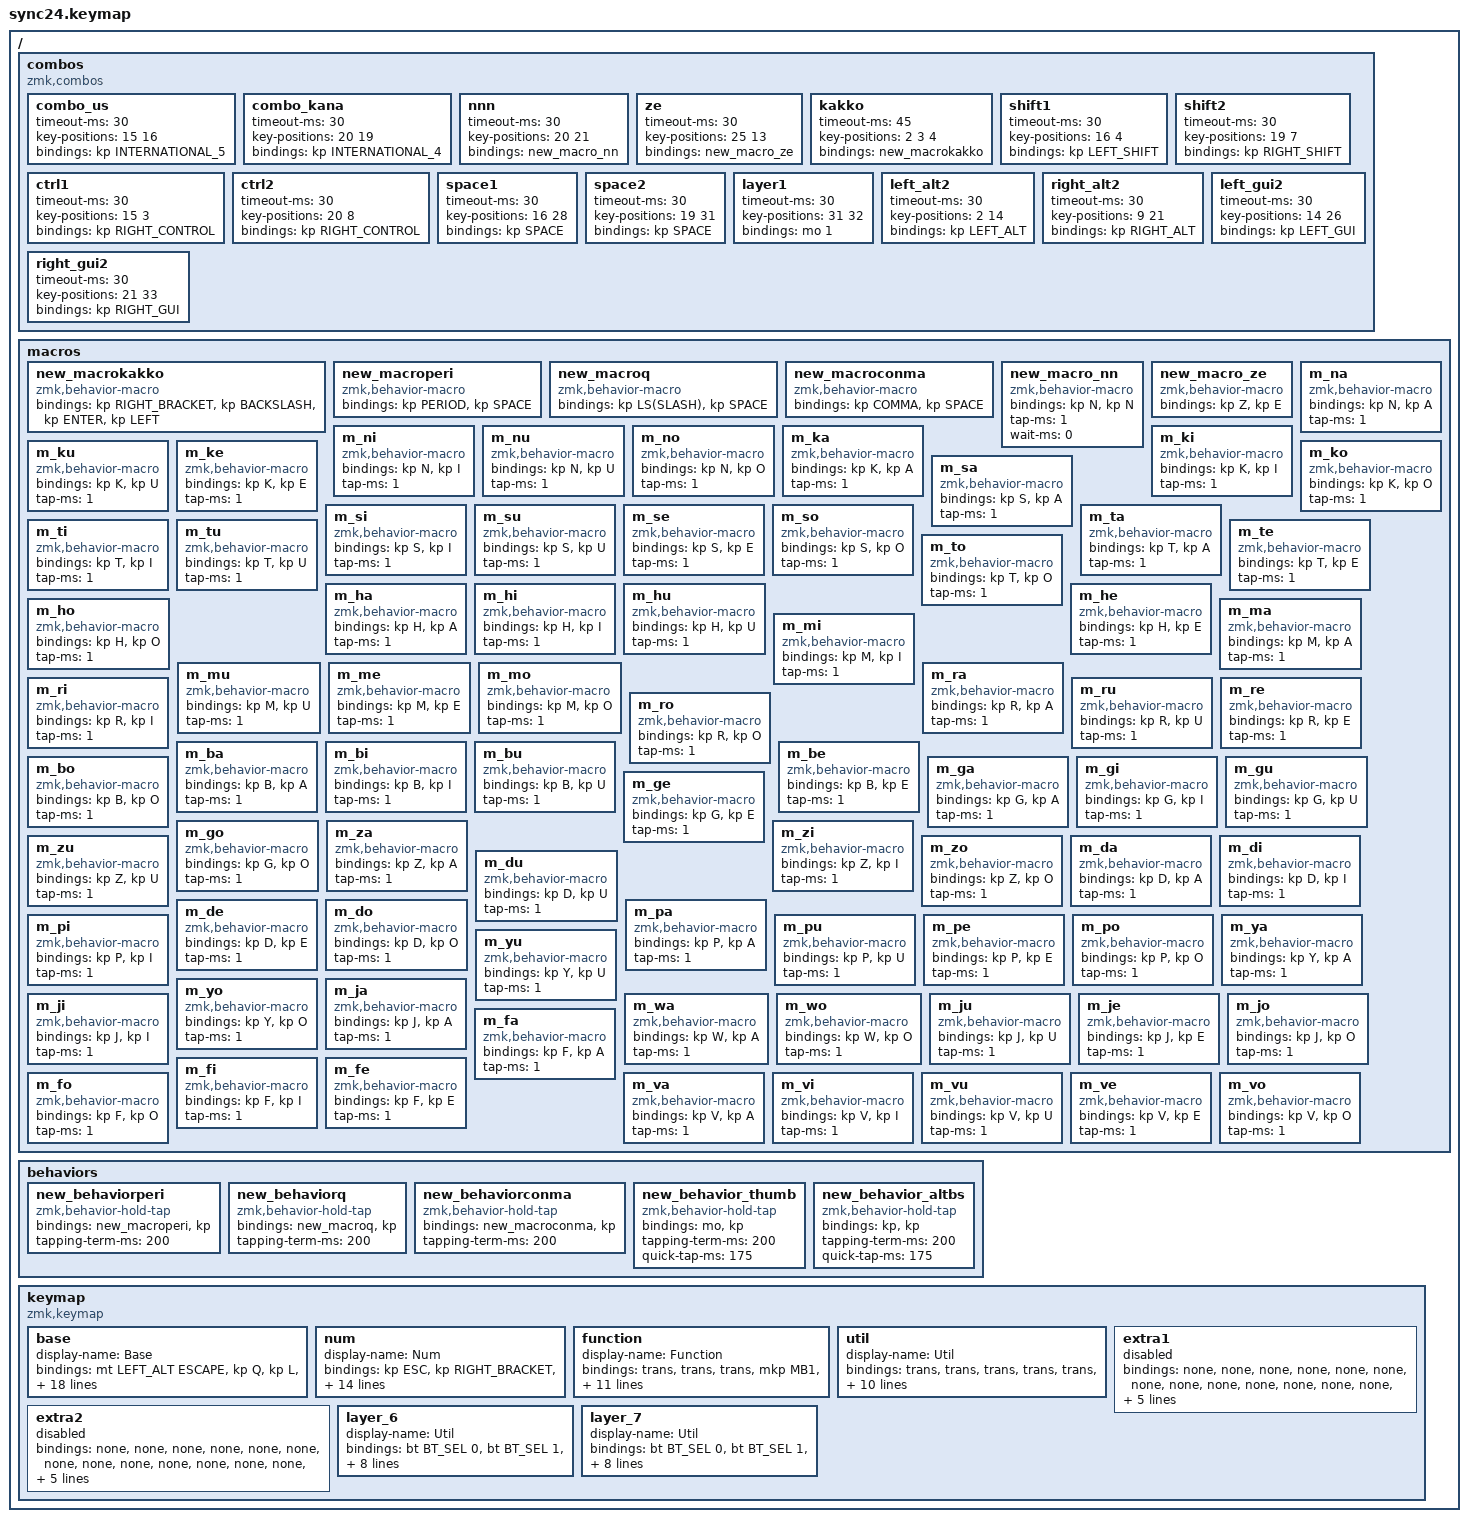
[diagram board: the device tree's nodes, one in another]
#define ZMK_BEHAVIORS_OMIT_KT

#undef ZMK_BEHAVIORS_KEEP_ALL

#define ZMK_BEHAVIORS_KEEP_SK
#define ZMK_BEHAVIORS_KEEP_MT
#define ZMK_BEHAVIORS_KEEP_KT

#include <behaviors.dtsi>
#include <dt-bindings/zmk/bt.h>
#include <dt-bindings/zmk/keys.h>
#include <dt-bindings/zmk/outputs.h>
#include <dt-bindings/zmk/pointing.h>

/ {
    /* ==========================================================================
       Combos
       ========================================================================== */

    combos {
        compatible = "zmk,combos";

        // 1. 特殊・ユーティリティ (最速判定)

        combo_us {
            timeout-ms = <30>;
            key-positions = <15 16>;
            bindings = <&kp INTERNATIONAL_5>;
        };

        combo_kana {
            timeout-ms = <30>;
            key-positions = <20 19>;
            bindings = <&kp INTERNATIONAL_4>;
        };

        nnn {
            timeout-ms = <30>;
            key-positions = <20 21>;
            bindings = <&new_macro_nn>;
        };

        ze {
            timeout-ms = <30>;
            key-positions = <25 13>;
            bindings = <&new_macro_ze>;
        };

        // 2. ★ 4文字・頻出語句コンボ (Timeout: 45ms)
        // んな // んに // んぬ // んね // んの // S+H+O+U // K+Y+O+U // T+Y+O+U // R+Y+O+U
        // ★ここを差し替え（です/ます等を A+O 系に変更し、末尾に . + Space）
        // A+O+T -> desu.(space) // A+O+S -> ました.(space) // A+O+D -> desita.(space) // A+O+N -> ます.(space) // A+O+N+S -> masenn.(space) // A+O+Y -> deshou.(space) // K+A+O // M+A+O // G+O+A // S+I+T+A
        // 3. 3文字コンボ (Timeout: 45ms)
        // 4. 2文字コンボ (Timeout: 30ms)
        // I+U どちらが先でもOK
        // 5. モディファイア・その他

        kakko {
            timeout-ms = <45>;
            key-positions = <2 3 4>;
            bindings = <&new_macrokakko>;
        };

        shift1 {
            timeout-ms = <30>;
            key-positions = <16 4>;
            bindings = <&kp LEFT_SHIFT>;
        };

        shift2 {
            timeout-ms = <30>;
            key-positions = <19 7>;
            bindings = <&kp RIGHT_SHIFT>;
        };

        ctrl1 {
            timeout-ms = <30>;
            key-positions = <15 3>;
            bindings = <&kp RIGHT_CONTROL>;
        };

        ctrl2 {
            timeout-ms = <30>;
            key-positions = <20 8>;
            bindings = <&kp RIGHT_CONTROL>;
        };

        space1 {
            timeout-ms = <30>;
            key-positions = <16 28>;
            bindings = <&kp SPACE>;
        };

        space2 {
            timeout-ms = <30>;
            key-positions = <19 31>;
            bindings = <&kp SPACE>;
        };

        layer1 {
            timeout-ms = <30>;
            key-positions = <31 32>;
            bindings = <&mo 1>;
        };

        left_alt2 {
            timeout-ms = <30>;
            key-positions = <2 14>;
            bindings = <&kp LEFT_ALT>;
        };

        right_alt2 {
            timeout-ms = <30>;
            key-positions = <9 21>;
            bindings = <&kp RIGHT_ALT>;
        };

        left_gui2 {
            timeout-ms = <30>;
            key-positions = <14 26>;
            bindings = <&kp LEFT_GUI>;
        };

        right_gui2 {
            timeout-ms = <30>;
            key-positions = <21 33>;
            bindings = <&kp RIGHT_GUI>;
        };
    };

    /* ==========================================================================
       Macros
       ========================================================================== */

    macros {
        new_macrokakko: new_macrokakko {
            compatible = "zmk,behavior-macro";
            #binding-cells = <0>;
            bindings = <&kp RIGHT_BRACKET &kp BACKSLASH &kp ENTER &kp LEFT>;
        };

        new_macroperi: new_macroperi {
            compatible = "zmk,behavior-macro";
            #binding-cells = <0>;
            bindings = <&kp PERIOD &kp SPACE>;
        };

        new_macroq: new_macroq {
            compatible = "zmk,behavior-macro";
            #binding-cells = <0>;
            bindings = <&kp LS(SLASH) &kp SPACE>;
        };

        new_macroconma: new_macroconma {
            compatible = "zmk,behavior-macro";
            #binding-cells = <0>;
            bindings = <&kp COMMA &kp SPACE>;
        };

        new_macro_nn: new_macro_nn {
            compatible = "zmk,behavior-macro";
            #binding-cells = <0>;
            bindings = <&kp N &kp N>;
            tap-ms = <1>;
            wait-ms = <0>;
        };

        new_macro_ze: new_macro_ze {
            compatible = "zmk,behavior-macro";
            #binding-cells = <0>;
            bindings = <&kp Z &kp E>;
        };

        // ★追加：末尾に「. + Space」を付ける版

        m_na: m_na {
            compatible = "zmk,behavior-macro";
            #binding-cells = <0>;
            bindings = <&kp N &kp A>;
            tap-ms = <1>;
        };

        m_ni: m_ni {
            compatible = "zmk,behavior-macro";
            #binding-cells = <0>;
            bindings = <&kp N &kp I>;
            tap-ms = <1>;
        };

        m_nu: m_nu {
            compatible = "zmk,behavior-macro";
            #binding-cells = <0>;
            bindings = <&kp N &kp U>;
            tap-ms = <1>;
        };

        m_no: m_no {
            compatible = "zmk,behavior-macro";
            #binding-cells = <0>;
            bindings = <&kp N &kp O>;
            tap-ms = <1>;
        };

        m_ka: m_ka {
            compatible = "zmk,behavior-macro";
            #binding-cells = <0>;
            bindings = <&kp K &kp A>;
            tap-ms = <1>;
        };

        m_ki: m_ki {
            compatible = "zmk,behavior-macro";
            #binding-cells = <0>;
            bindings = <&kp K &kp I>;
            tap-ms = <1>;
        };

        m_ku: m_ku {
            compatible = "zmk,behavior-macro";
            #binding-cells = <0>;
            bindings = <&kp K &kp U>;
            tap-ms = <1>;
        };

        m_ke: m_ke {
            compatible = "zmk,behavior-macro";
            #binding-cells = <0>;
            bindings = <&kp K &kp E>;
            tap-ms = <1>;
        };

        m_ko: m_ko {
            compatible = "zmk,behavior-macro";
            #binding-cells = <0>;
            bindings = <&kp K &kp O>;
            tap-ms = <1>;
        };

        m_sa: m_sa {
            compatible = "zmk,behavior-macro";
            #binding-cells = <0>;
            bindings = <&kp S &kp A>;
            tap-ms = <1>;
        };

        m_si: m_si {
            compatible = "zmk,behavior-macro";
            #binding-cells = <0>;
            bindings = <&kp S &kp I>;
            tap-ms = <1>;
        };

        m_su: m_su {
            compatible = "zmk,behavior-macro";
            #binding-cells = <0>;
            bindings = <&kp S &kp U>;
            tap-ms = <1>;
        };

        m_se: m_se {
            compatible = "zmk,behavior-macro";
            #binding-cells = <0>;
            bindings = <&kp S &kp E>;
            tap-ms = <1>;
        };

        m_so: m_so {
            compatible = "zmk,behavior-macro";
            #binding-cells = <0>;
            bindings = <&kp S &kp O>;
            tap-ms = <1>;
        };

        m_ta: m_ta {
            compatible = "zmk,behavior-macro";
            #binding-cells = <0>;
            bindings = <&kp T &kp A>;
            tap-ms = <1>;
        };

        m_ti: m_ti {
            compatible = "zmk,behavior-macro";
            #binding-cells = <0>;
            bindings = <&kp T &kp I>;
            tap-ms = <1>;
        };

        m_tu: m_tu {
            compatible = "zmk,behavior-macro";
            #binding-cells = <0>;
            bindings = <&kp T &kp U>;
            tap-ms = <1>;
        };

        m_te: m_te {
            compatible = "zmk,behavior-macro";
            #binding-cells = <0>;
            bindings = <&kp T &kp E>;
            tap-ms = <1>;
        };

        m_to: m_to {
            compatible = "zmk,behavior-macro";
            #binding-cells = <0>;
            bindings = <&kp T &kp O>;
            tap-ms = <1>;
        };

        m_ha: m_ha {
            compatible = "zmk,behavior-macro";
            #binding-cells = <0>;
            bindings = <&kp H &kp A>;
            tap-ms = <1>;
        };

        m_hi: m_hi {
            compatible = "zmk,behavior-macro";
            #binding-cells = <0>;
            bindings = <&kp H &kp I>;
            tap-ms = <1>;
        };

        m_hu: m_hu {
            compatible = "zmk,behavior-macro";
            #binding-cells = <0>;
            bindings = <&kp H &kp U>;
            tap-ms = <1>;
        };

        m_he: m_he {
            compatible = "zmk,behavior-macro";
            #binding-cells = <0>;
            bindings = <&kp H &kp E>;
            tap-ms = <1>;
        };

        m_ho: m_ho {
            compatible = "zmk,behavior-macro";
            #binding-cells = <0>;
            bindings = <&kp H &kp O>;
            tap-ms = <1>;
        };

        m_ma: m_ma {
            compatible = "zmk,behavior-macro";
            #binding-cells = <0>;
            bindings = <&kp M &kp A>;
            tap-ms = <1>;
        };

        m_mi: m_mi {
            compatible = "zmk,behavior-macro";
            #binding-cells = <0>;
            bindings = <&kp M &kp I>;
            tap-ms = <1>;
        };

        m_mu: m_mu {
            compatible = "zmk,behavior-macro";
            #binding-cells = <0>;
            bindings = <&kp M &kp U>;
            tap-ms = <1>;
        };

        m_me: m_me {
            compatible = "zmk,behavior-macro";
            #binding-cells = <0>;
            bindings = <&kp M &kp E>;
            tap-ms = <1>;
        };

        m_mo: m_mo {
            compatible = "zmk,behavior-macro";
            #binding-cells = <0>;
            bindings = <&kp M &kp O>;
            tap-ms = <1>;
        };

        m_ra: m_ra {
            compatible = "zmk,behavior-macro";
            #binding-cells = <0>;
            bindings = <&kp R &kp A>;
            tap-ms = <1>;
        };

        m_ri: m_ri {
            compatible = "zmk,behavior-macro";
            #binding-cells = <0>;
            bindings = <&kp R &kp I>;
            tap-ms = <1>;
        };

        m_ru: m_ru {
            compatible = "zmk,behavior-macro";
            #binding-cells = <0>;
            bindings = <&kp R &kp U>;
            tap-ms = <1>;
        };

        m_re: m_re {
            compatible = "zmk,behavior-macro";
            #binding-cells = <0>;
            bindings = <&kp R &kp E>;
            tap-ms = <1>;
        };

        m_ro: m_ro {
            compatible = "zmk,behavior-macro";
            #binding-cells = <0>;
            bindings = <&kp R &kp O>;
            tap-ms = <1>;
        };

        m_ba: m_ba {
            compatible = "zmk,behavior-macro";
            #binding-cells = <0>;
            bindings = <&kp B &kp A>;
            tap-ms = <1>;
        };

        m_bi: m_bi {
            compatible = "zmk,behavior-macro";
            #binding-cells = <0>;
            bindings = <&kp B &kp I>;
            tap-ms = <1>;
        };

        m_bu: m_bu {
            compatible = "zmk,behavior-macro";
            #binding-cells = <0>;
            bindings = <&kp B &kp U>;
            tap-ms = <1>;
        };

        m_be: m_be {
            compatible = "zmk,behavior-macro";
            #binding-cells = <0>;
            bindings = <&kp B &kp E>;
            tap-ms = <1>;
        };

        m_bo: m_bo {
            compatible = "zmk,behavior-macro";
            #binding-cells = <0>;
            bindings = <&kp B &kp O>;
            tap-ms = <1>;
        };

        m_ga: m_ga {
            compatible = "zmk,behavior-macro";
            #binding-cells = <0>;
            bindings = <&kp G &kp A>;
            tap-ms = <1>;
        };

        m_gi: m_gi {
            compatible = "zmk,behavior-macro";
            #binding-cells = <0>;
            bindings = <&kp G &kp I>;
            tap-ms = <1>;
        };

        m_gu: m_gu {
            compatible = "zmk,behavior-macro";
            #binding-cells = <0>;
            bindings = <&kp G &kp U>;
            tap-ms = <1>;
        };

        m_ge: m_ge {
            compatible = "zmk,behavior-macro";
            #binding-cells = <0>;
            bindings = <&kp G &kp E>;
            tap-ms = <1>;
        };

        m_go: m_go {
            compatible = "zmk,behavior-macro";
            #binding-cells = <0>;
            bindings = <&kp G &kp O>;
            tap-ms = <1>;
        };

        m_za: m_za {
            compatible = "zmk,behavior-macro";
            #binding-cells = <0>;
            bindings = <&kp Z &kp A>;
            tap-ms = <1>;
        };

        m_zi: m_zi {
            compatible = "zmk,behavior-macro";
            #binding-cells = <0>;
            bindings = <&kp Z &kp I>;
            tap-ms = <1>;
        };

        m_zu: m_zu {
            compatible = "zmk,behavior-macro";
            #binding-cells = <0>;
            bindings = <&kp Z &kp U>;
            tap-ms = <1>;
        };

        m_zo: m_zo {
            compatible = "zmk,behavior-macro";
            #binding-cells = <0>;
            bindings = <&kp Z &kp O>;
            tap-ms = <1>;
        };

        m_da: m_da {
            compatible = "zmk,behavior-macro";
            #binding-cells = <0>;
            bindings = <&kp D &kp A>;
            tap-ms = <1>;
        };

        m_di: m_di {
            compatible = "zmk,behavior-macro";
            #binding-cells = <0>;
            bindings = <&kp D &kp I>;
            tap-ms = <1>;
        };

        m_du: m_du {
            compatible = "zmk,behavior-macro";
            #binding-cells = <0>;
            bindings = <&kp D &kp U>;
            tap-ms = <1>;
        };

        m_de: m_de {
            compatible = "zmk,behavior-macro";
            #binding-cells = <0>;
            bindings = <&kp D &kp E>;
            tap-ms = <1>;
        };

        m_do: m_do {
            compatible = "zmk,behavior-macro";
            #binding-cells = <0>;
            bindings = <&kp D &kp O>;
            tap-ms = <1>;
        };

        m_pa: m_pa {
            compatible = "zmk,behavior-macro";
            #binding-cells = <0>;
            bindings = <&kp P &kp A>;
            tap-ms = <1>;
        };

        m_pi: m_pi {
            compatible = "zmk,behavior-macro";
            #binding-cells = <0>;
            bindings = <&kp P &kp I>;
            tap-ms = <1>;
        };

        m_pu: m_pu {
            compatible = "zmk,behavior-macro";
            #binding-cells = <0>;
            bindings = <&kp P &kp U>;
            tap-ms = <1>;
        };

        m_pe: m_pe {
            compatible = "zmk,behavior-macro";
            #binding-cells = <0>;
            bindings = <&kp P &kp E>;
            tap-ms = <1>;
        };

        m_po: m_po {
            compatible = "zmk,behavior-macro";
            #binding-cells = <0>;
            bindings = <&kp P &kp O>;
            tap-ms = <1>;
        };

        m_ya: m_ya {
            compatible = "zmk,behavior-macro";
            #binding-cells = <0>;
            bindings = <&kp Y &kp A>;
            tap-ms = <1>;
        };

        m_yu: m_yu {
            compatible = "zmk,behavior-macro";
            #binding-cells = <0>;
            bindings = <&kp Y &kp U>;
            tap-ms = <1>;
        };

        m_yo: m_yo {
            compatible = "zmk,behavior-macro";
            #binding-cells = <0>;
            bindings = <&kp Y &kp O>;
            tap-ms = <1>;
        };

        m_wa: m_wa {
            compatible = "zmk,behavior-macro";
            #binding-cells = <0>;
            bindings = <&kp W &kp A>;
            tap-ms = <1>;
        };

        m_wo: m_wo {
            compatible = "zmk,behavior-macro";
            #binding-cells = <0>;
            bindings = <&kp W &kp O>;
            tap-ms = <1>;
        };

        m_ja: m_ja {
            compatible = "zmk,behavior-macro";
            #binding-cells = <0>;
            bindings = <&kp J &kp A>;
            tap-ms = <1>;
        };

        m_ji: m_ji {
            compatible = "zmk,behavior-macro";
            #binding-cells = <0>;
            bindings = <&kp J &kp I>;
            tap-ms = <1>;
        };

        m_ju: m_ju {
            compatible = "zmk,behavior-macro";
            #binding-cells = <0>;
            bindings = <&kp J &kp U>;
            tap-ms = <1>;
        };

        m_je: m_je {
            compatible = "zmk,behavior-macro";
            #binding-cells = <0>;
            bindings = <&kp J &kp E>;
            tap-ms = <1>;
        };

        m_jo: m_jo {
            compatible = "zmk,behavior-macro";
            #binding-cells = <0>;
            bindings = <&kp J &kp O>;
            tap-ms = <1>;
        };

        m_fa: m_fa {
            compatible = "zmk,behavior-macro";
            #binding-cells = <0>;
            bindings = <&kp F &kp A>;
            tap-ms = <1>;
        };

        m_fi: m_fi {
            compatible = "zmk,behavior-macro";
            #binding-cells = <0>;
            bindings = <&kp F &kp I>;
            tap-ms = <1>;
        };

        m_fe: m_fe {
            compatible = "zmk,behavior-macro";
            #binding-cells = <0>;
            bindings = <&kp F &kp E>;
            tap-ms = <1>;
        };

        m_fo: m_fo {
            compatible = "zmk,behavior-macro";
            #binding-cells = <0>;
            bindings = <&kp F &kp O>;
            tap-ms = <1>;
        };

        m_va: m_va {
            compatible = "zmk,behavior-macro";
            #binding-cells = <0>;
            bindings = <&kp V &kp A>;
            tap-ms = <1>;
        };

        m_vi: m_vi {
            compatible = "zmk,behavior-macro";
            #binding-cells = <0>;
            bindings = <&kp V &kp I>;
            tap-ms = <1>;
        };

        m_vu: m_vu {
            compatible = "zmk,behavior-macro";
            #binding-cells = <0>;
            bindings = <&kp V &kp U>;
            tap-ms = <1>;
        };

        m_ve: m_ve {
            compatible = "zmk,behavior-macro";
            #binding-cells = <0>;
            bindings = <&kp V &kp E>;
            tap-ms = <1>;
        };

        m_vo: m_vo {
            compatible = "zmk,behavior-macro";
            #binding-cells = <0>;
            bindings = <&kp V &kp O>;
            tap-ms = <1>;
        };
    };

    /* ==========================================================================
       Behaviors
       ========================================================================== */

    behaviors {
        new_behaviorperi: new_behaviorperi {
            compatible = "zmk,behavior-hold-tap";
            bindings = <&new_macroperi>, <&kp>;

            #binding-cells = <2>;
            tapping-term-ms = <200>;
        };

        new_behaviorq: new_behaviorq {
            compatible = "zmk,behavior-hold-tap";
            bindings = <&new_macroq>, <&kp>;

            #binding-cells = <2>;
            tapping-term-ms = <200>;
        };

        new_behaviorconma: new_behaviorconma {
            compatible = "zmk,behavior-hold-tap";
            bindings = <&new_macroconma>, <&kp>;

            #binding-cells = <2>;
            tapping-term-ms = <200>;
        };

        new_behavior_thumb: new_behavior_thumb {
            compatible = "zmk,behavior-hold-tap";
            bindings = <&mo>, <&kp>;

            #binding-cells = <2>;
            tapping-term-ms = <200>;
            quick-tap-ms = <175>;
        };

        new_behavior_altbs: new_behavior_altbs {
            compatible = "zmk,behavior-hold-tap";
            bindings = <&kp>, <&kp>;

            #binding-cells = <2>;
            tapping-term-ms = <200>;
            quick-tap-ms = <175>;
        };
    };

    /* ==========================================================================
       Keymap
       ========================================================================== */

    keymap {
        compatible = "zmk,keymap";

        base {
            display-name = "Base";
            bindings = <
&mt LEFT_ALT ESCAPE  &kp Q  &kp L  &kp U  &new_behaviorperi 0 PERIOD  &kp MINUS  &kp F  &kp W  &kp R  &kp Y  &kp P  &new_behavior_altbs RIGHT_ALT BACKSPACE  &new_behavior_thumb 1 TAB  &kp E  &kp I  &kp A  &kp O  &new_behaviorconma 0 COMMA  &kp D  &kp T  &kp N  &kp S  &kp H  &kp RET  &new_behavior_altbs LSHFT PAGE_UP  &kp Z  &mt LEFT_SHIFT X  &new_behavior_thumb 2 C  &new_behavior_thumb 1 V  &new_behaviorq 0 SLASH  &kp G  &kp K  &kp M  &kp J  &kp B  &new_behavior_altbs RSHIFT PAGE_DOWN  &kp LEFT_CONTROL  &kp LEFT_GUI  &kp LALT  &lt 1 TAB  &mo 2  &mt LEFT_CONTROL SPACE  &mt LEFT_CONTROL SPACE  &new_behavior_thumb 3 BACKSPACE  &kp LEFT_ARROW  &kp UP_ARROW  &kp DOWN_ARROW  &kp RIGHT
            >;
        };

        num {
            display-name = "Num";
            bindings = <
&kp ESC  &kp RIGHT_BRACKET  &kp BACKSLASH  &kp SEMICOLON  &kp LBKT  &kp EQUAL  &kp MINUS  &kp BSPC  &kp UP_ARROW  &kp DEL  &trans  &kp DEL  &kp LCMD  &kp APOS  &kp LS(INTERNATIONAL_3)  &kp LS(INTERNATIONAL_1)  &kp INTERNATIONAL_3  &kp LS(N9)  &kp HOME  &kp LEFT_ARROW  &kp DOWN_ARROW  &kp RIGHT_ARROW  &kp LCTRL  &trans  &kp LSHFT  &kp LEFT_ALT  &kp LSHFT  &kp LGUI  &kp LS(LEFT_BRACE)  &kp RIGHT_BRACE  &kp END  &kp ESCAPE  &kp PAGE_UP  &kp PAGE_DOWN  &kp RIGHT_ALT  &kp RSHFT  &kp LSHFT  &trans  &trans  &kp LS(K_APP)  &kp K_APP  &trans  &trans  &trans  &kp HOME  &kp PAGE_UP  &kp PAGE_DOWN  &kp END
            >;
        };

        function {
            display-name = "Function";
            bindings = <
&trans  &trans  &trans  &mkp MB1  &mkp MB2  &trans  &kp BSPC  &kp N7  &kp N8  &kp N9  &kp KP_MINUS  &kp INS  &trans  &kp C_VOLUME_DOWN  &kp C_VOLUME_UP  &kp LS(K_APP)  &kp K_APP  &kp EQUAL  &kp KP_ASTERISK  &kp N4  &kp N5  &kp N6  &kp KP_PLUS  &trans  &trans  &trans  &kp LEFT_SHIFT  &kp LC(C)  &kp LA(LC(V))  &trans  &kp KP_COMMA  &kp N1  &kp N2  &kp N3  &kp KP_SLASH  &kp KP_DOT  &mo 3  &trans  &trans  &mkp MB1  &mkp MB2  &trans  &trans  &kp N0  &kp HOME  &kp PAGE_UP  &kp PAGE_DOWN  &kp END
            >;
        };

        util {
            display-name = "Util";
            bindings = <
&trans  &trans  &trans  &trans  &trans  &trans  &trans  &kp F7  &kp F8  &kp F9  &kp F12  &kp DEL  &trans  &trans  &trans  &trans  &trans  &out OUT_USB  &trans  &kp F4  &kp F5  &kp F6  &kp F11  &trans  &trans  &kp LG(LS(PRINTSCREEN))  &kp PRINTSCREEN  &trans  &trans  &kp A  &trans  &kp F1  &kp F2  &kp F3  &kp F10  &trans  &trans  &trans  &trans  &trans  &trans  &kp LEFT_SHIFT  &kp RIGHT_SHIFT  &trans  &kp HOME  &kp PAGE_UP  &kp PAGE_DOWN  &kp END
            >;
        };

        extra1 {
            status = "reserved";
            bindings = <
&none  &none  &none  &none  &none  &none  &none  &none  &none  &none  &none  &none  &none  &none  &none  &none  &none  &none  &none  &none  &none  &none  &none  &none  &none  &none  &none  &none  &none  &none  &none  &none  &none  &none  &none  &none  &none  &none  &none  &none  &none  &none  &none  &none  &none  &none  &none  &none
            >;
        };

        extra2 {
            status = "reserved";
            bindings = <
&none  &none  &none  &none  &none  &none  &none  &none  &none  &none  &none  &none  &none  &none  &none  &none  &none  &none  &none  &none  &none  &none  &none  &none  &none  &none  &none  &none  &none  &none  &none  &none  &none  &none  &none  &none  &none  &none  &none  &none  &none  &none  &none  &none  &none  &none  &none  &none
            >;
        };

        layer_6 {
            display-name = "Util";
            bindings = <
&bt BT_SEL 0  &bt BT_SEL 1  &bt BT_SEL 2  &bt BT_SEL 3  &bt BT_SEL 4  &bt BT_CLR  &none  &none  &none  &none  &none  &none  &studio_unlock  &none  &none  &none  &none  &none  &none  &none  &none  &none  &none  &none  &none  &none  &none  &none  &none  &none  &none  &none  &none  &none  &none  &none  &none  &none  &none  &none  &none  &none  &none  &none  &none  &none  &none  &none
            >;
        };

        layer_7 {
            display-name = "Util";
            bindings = <
&bt BT_SEL 0  &bt BT_SEL 1  &bt BT_SEL 2  &bt BT_SEL 3  &bt BT_SEL 4  &bt BT_CLR  &none  &none  &none  &none  &none  &none  &studio_unlock  &none  &none  &none  &none  &none  &none  &none  &none  &none  &none  &none  &none  &none  &none  &none  &none  &none  &none  &none  &none  &none  &none  &none  &none  &none  &none  &none  &none  &none  &none  &none  &none  &none  &none  &none
            >;
        };
    };
};
